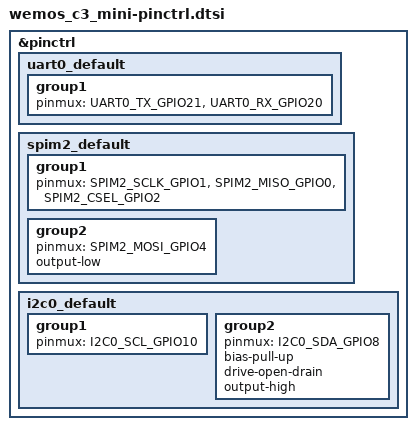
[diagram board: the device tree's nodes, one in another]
/*
 * SPDX-License-Identifier: Apache-2.0
 */

#include <zephyr/dt-bindings/pinctrl/esp-pinctrl-common.h>
#include <dt-bindings/pinctrl/esp32c3-pinctrl.h>
#include <zephyr/dt-bindings/pinctrl/esp32c3-gpio-sigmap.h>

&pinctrl {
  uart0_default: uart0_default {
    group1 {
      pinmux =
        <UART0_TX_GPIO21>,
        <UART0_RX_GPIO20>;
    };
  };

  spim2_default: spim2_default {
    group1 {
      pinmux =
        <SPIM2_SCLK_GPIO1>,
        <SPIM2_MISO_GPIO0>,
        <SPIM2_CSEL_GPIO2>;
    };
    group2 {
      pinmux = <SPIM2_MOSI_GPIO4>;
      output-low;
    };
  };

  i2c0_default: i2c0_default {
    group1 {
      // pinmux =
      //   <I2C0_SDA_GPIO10>,
      //   <I2C0_SCL_GPIO8>;
      // bias-pull-up;
      // drive-open-drain;
      // output-high;
      pinmux = <I2C0_SCL_GPIO10>;
    };
    group2 {
      pinmux = <I2C0_SDA_GPIO8>;
      bias-pull-up;
      drive-open-drain;
      output-high;
    };
  };
};
